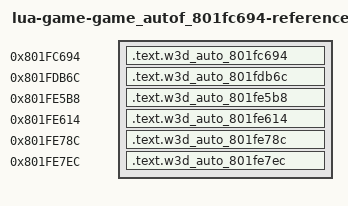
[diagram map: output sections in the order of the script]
/* Generated reference-only placements. All bodies are source-built. */
OUTPUT_FORMAT("elf32-powerpc")
OUTPUT_ARCH(powerpc)
ENTRY(w3d_auto_801fc694)
_SDA_BASE_ = 0x804b2540;
_SDA2_BASE_ = 0x804c2540;
fn_8016DF8C = 0x8016df8c;
fn_8020BD38 = 0x8020bd38;
fn_8020D878 = 0x8020d878;
fn_8020D8F8 = 0x8020d8f8;
fn_802ED89C = 0x802ed89c;
lbl_803B29A4 = 0x803b29a4;
lbl_8045E9C8 = 0x8045e9c8;
SECTIONS {
  .text.w3d_auto_801fc694 0x801fc694 : { *(.text.w3d_auto_801fc694) }
  .text.w3d_auto_801fdb6c 0x801fdb6c : { *(.text.w3d_auto_801fdb6c) }
  .text.w3d_auto_801fe5b8 0x801fe5b8 : { *(.text.w3d_auto_801fe5b8) }
  .text.w3d_auto_801fe614 0x801fe614 : { *(.text.w3d_auto_801fe614) }
  .text.w3d_auto_801fe78c 0x801fe78c : { *(.text.w3d_auto_801fe78c) }
  .text.w3d_auto_801fe7ec 0x801fe7ec : { *(.text.w3d_auto_801fe7ec) }
  /DISCARD/ : { *(.text*) *(.rodata*) *(.data*) *(.bss*) *(.sdata*) *(.sbss*) *(.comment) }
}
